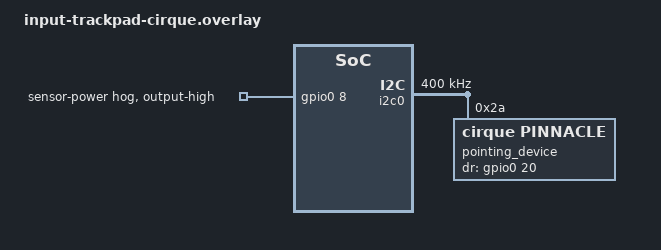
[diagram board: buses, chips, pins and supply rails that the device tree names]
/*
 * Cirque TM040040 (Pinnacle 1CA027) on the torabo-tsuki LP 6-pin sensor
 * connector, I2C mode. Use instead of input-trackball / input-trackpad.
 *
 * Connector  MCU    Function     TM040040 pad (FFC pin)
 *   1        GND    GND          GND  (11)
 *   2        P0.18  SDA          SDA  (10)
 *   3        P0.16  SCL          SCL  (9)
 *   4        P0.19  (unused)     -
 *   5        P0.20  DR (HW_DR)   DR   (4)
 *   6        VCC    VDD 3.3V     VDD  (12)
 *
 * Remove the trackpad's R1 (470k) to put it in I2C mode, and fit 4.7k
 * pull-ups on SDA/SCL (the adapter's R1/R2): the trackpad has none.
 */

#include <zephyr/dt-bindings/gpio/nordic-nrf-gpio.h>

/* Sensor power enable. The stock trackball/trackpad drivers drive P0.08
 * through their power-gpios property; the Cirque driver has none, so hold
 * it high from boot with a GPIO hog. */
&gpio0 {
    sensor_power_hog {
        gpio-hog;
        gpios = <8 (GPIO_ACTIVE_HIGH | NRF_GPIO_DRIVE_H0H1)>;
        output-high;
        line-name = "sensor-power";
    };
};

&i2c0 {
    status = "okay";
    compatible = "nordic,nrf-twim";
    pinctrl-0 = <&i2c0_default>;   /* SDA P0.18, SCL P0.16, from the shield */
    pinctrl-1 = <&i2c0_sleep>;
    pinctrl-names = "default", "sleep";
    clock-frequency = <I2C_BITRATE_FAST>;

    pointing_device: trackpad@2a {
        status = "okay";
        compatible = "cirque,pinnacle";
        reg = <0x2a>;
        dr-gpios = <&gpio0 20 (GPIO_ACTIVE_HIGH | GPIO_PULL_DOWN)>;
        sensitivity = "2x";

        /*
         * Absolute mode: the pad reports finger position (0..1024 on both
         * axes) and the tp_gestures processor turns it into cursor motion,
         * glide, taps, right-click and circular edge scroll.
         * Orientation is set in tp_processors.dtsi (invert-x / invert-y),
         * not here.
         *
         * No `sleep;`: the pad's own sleep checks for a finger only every
         * 255 ms, which made the first movement after a short pause laggy.
         * The pad still sleeps when the whole keyboard goes idle
         * (CONFIG_ZMK_INPUT_PINNACLE_IDLE_SLEEPER).
         */
        absolute-mode;
        /* ignore faint touches (hover, noise) that made the cursor float.
         * Z is touch strength 0..63; the debug log shows your real values. */
        absolute-mode-z-min = <3>;
    };
};
